# S32R372 register map
Vendor: Freescale Semiconductor, Inc.; Series: Qorivva; File version: 1.6
Registers are 32-bit, read-write, reset 0x0 unless marked. A register's access mark holds for its fields unless they carry their own. Offsets are from the block's base; [hi:lo] are bit positions; {n}, {i} and the like mark numbered series; 'fields as' and 'values as' point back to an identical list.

## MC_ME
Base 0xFFFB8000; register names take the prefix MC_ME_
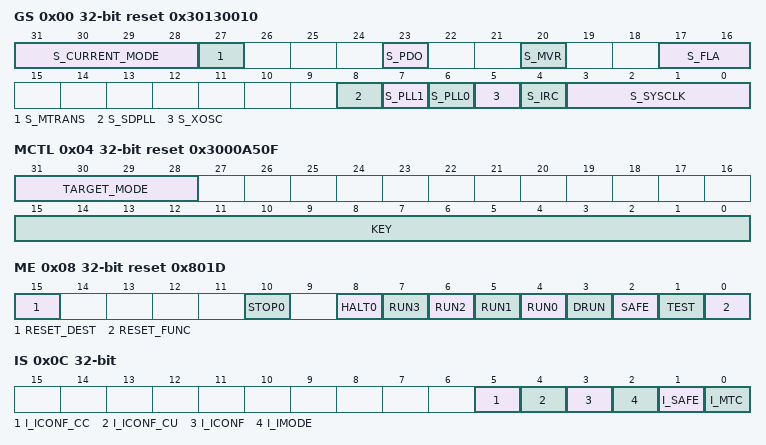
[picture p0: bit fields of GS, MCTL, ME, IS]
0x00 GS ro reset 0x30130010 — Global Status Register
  [31:28] S_CURRENT_MODE — Current chip mode status
    0=RESET; 1=TEST; 2=SAFE; 3=DRUN; {v}=RUN{v-4} (v=4..7); 8=HALT0; 10=STOP0
  [27] S_MTRANS — Mode transition status
    0=Mode transition process is not active; 1=Mode transition is ongoing
  [23] S_PDO — Output power-down status - This bit specifies output power-down status of I/Os
    0=No automatic safe gating of I/Os used and pads power sequence driver is enabled; 1=In SAFE/TEST modes, outputs of pads are forced to high impedance state and the pads power sequence driver is disabled. The inputs are level unchanged. In STOP0 mode, only the pad power sequence driver is disabled, but the state of the output remains functional.
  [20] S_MVR — Main voltage regulator status
    0=Main voltage regulator is not ready; 1=Main voltage regulator is ready for use
  [17:16] S_FLA — Flash availability status
    3=Flash is in normal mode and available for use
  [8] S_SDPLL — SDPLL status
    0=SDPLL is not stable; 1=SDPLL is providing a stable clock
  [7] S_PLL1 — PLL1 status
    0=PLL1 is not stable; 1=PLL1 is providing a stable clock
  [6] S_PLL0 — PLL0 status
    0=PLL0 is not stable; 1=PLL0 is providing a stable clock
  [5] S_XOSC — XOSC status S_XOSC alone should not be relied on
    0=XOSC is not stable; 1=XOSC is providing a stable clock
  [4] S_IRC — IRC status
    0=IRC is not stable; 1=IRC is providing a stable clock
  [3:0] S_SYSCLK — System clock switch status - These bits specify the system clock currently used by the system.
    0=IRC_CLK; 1=XOSC_CLK; 2=PLL0_PHI_CLK; 4=PLL1_PHI_CLK; 15=system clock is disabled
0x04 MCTL reset 0x3000A50F — Mode Control Register
  [31:28] TARGET_MODE — Target chip mode - These bits provide the target chip mode to be entered by software programming
    0=RESET (triggers a 'functional' reset event); 1=TEST; 2=SAFE; 3=DRUN; {v}=RUN{v-4} (v=4..7); 8=HALT0; 10=STOP0; 15=RESET (triggers a 'destructive' reset event)
  [15:0] KEY wo — Control key - These bits enable write access to this register
0x08 ME reset 0x801D — Mode Enable Register
  [15] RESET_DEST ro — 'destructive' RESET mode enable
    1='destructive' RESET mode is enabled
  [10] STOP0 — STOP0 mode enable
    0=STOP0 mode is disabled; 1=STOP0 mode is enabled
  [8] HALT0 — HALT0 mode enable
    0=HALT0 mode is disabled; 1=HALT0 mode is enabled
  [7] RUN3 — RUN3 mode enable
    0=RUN3 mode is disabled; 1=RUN3 mode is enabled
  [6] RUN2 — RUN2 mode enable
    0=RUN2 mode is disabled; 1=RUN2 mode is enabled
  [5] RUN1 — RUN1 mode enable
    0=RUN1 mode is disabled; 1=RUN1 mode is enabled
  [4] RUN0 ro — RUN0 mode enable
    1=RUN0 mode is enabled
  [3] DRUN ro — DRUN mode enable
    1=DRUN mode is enabled
  [2] SAFE ro — SAFE mode enable
    1=SAFE mode is enabled
  [1] TEST — TEST mode enable
    0=TEST mode is disabled; 1=TEST mode is enabled
  [0] RESET_FUNC ro — 'functional' RESET mode enable
    1='functional' RESET mode is enabled
0x0C IS — Interrupt Status Register
  [5] I_ICONF_CC — Invalid mode configuration interrupt (core configuration) - This bit is set if a write access to one of the ME_CADDRn registers is attempted while a mode transition is in progress
    0=No write to an ME_CADDRn register was attempted during an ongoing mode transition; 1=A write to an ME_CADDRn register was attempted during an ongoing mode transition
  [4] I_ICONF_CU — Invalid mode configuration interrupt (Clock Usage) - This bit is set during a mode transition if a clock which is required to be on by an enabled peripheral is configured to be turned off
    0=No invalid mode configuration (clock usage) interrupt occurred; 1=Invalid mode configuration (clock usage) interrupt is pending
  [3] I_ICONF — Invalid mode configuration interrupt - This bit is set whenever a write operation to ME_<mode>_MC registers with invalid mode configuration is attempted
    0=No invalid mode configuration interrupt occurred; 1=Invalid mode configuration interrupt is pending
  [2] I_IMODE — Invalid mode interrupt - This bit is set whenever an invalid mode transition is requested
    0=No invalid mode interrupt occurred; 1=Invalid mode interrupt is pending
  [1] I_SAFE — SAFE mode interrupt - This bit is set whenever the chip enters SAFE mode on hardware requests generated in the system
    0=No SAFE mode interrupt occurred; 1=SAFE mode interrupt is pending
  [0] I_MTC — Mode transition complete interrupt - This bit is set whenever the mode transition process completes (S_MTRANS transits from 1 to 0)
    0=No mode transition complete interrupt occurred; 1=Mode transition complete interrupt is pending
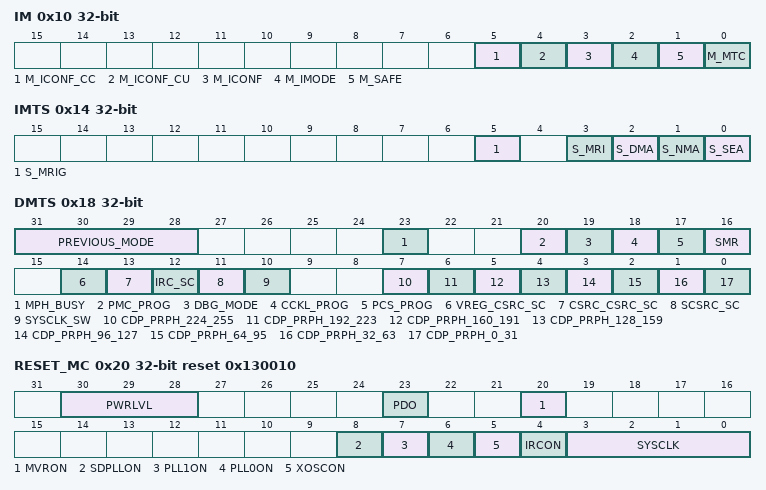
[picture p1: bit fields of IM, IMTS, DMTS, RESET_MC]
0x10 IM — Interrupt Mask Register
  [5] M_ICONF_CC — Invalid mode configuration (core configuration) interrupt mask
    0=Invalid mode interrupt is masked; 1=Invalid mode interrupt is enabled
  [4] M_ICONF_CU — Invalid mode configuration (clock usage) interrupt mask
    values as M_ICONF_CC
  [3] M_ICONF — Invalid mode configuration interrupt mask
    values as M_ICONF_CC
  [2] M_IMODE — Invalid mode interrupt mask
    values as M_ICONF_CC
  [1] M_SAFE — SAFE mode interrupt mask
    0=SAFE mode interrupt is masked; 1=SAFE mode interrupt is enabled
  [0] M_MTC — Mode transition complete interrupt mask
    0=Mode transition complete interrupt is masked; 1=Mode transition complete interrupt is enabled
0x14 IMTS — Invalid Mode Transition Status Register
  [5] S_MRIG — S_MRIG Mode Request Ignored status - This bit is set whenever a new mode is requested while a transition to the SAFE mode is in progress
  [3] S_MRI — Mode Request Illegal status - This bit is set whenever the target mode requested is not a valid mode with respect to current mode
    0=Target mode requested is not illegal with respect to current mode; 1=Target mode requested is illegal with respect to current mode
  [2] S_DMA — Disabled Mode Access status - This bit is set whenever the target mode requested is one of those disabled modes determined by ME_ME register
    0=Target mode requested is not a disabled mode; 1=Target mode requested is a disabled mode
  [1] S_NMA — Non-existing Mode Access status - This bit is set whenever the target mode requested is one of those non existing modes determined by ME_ME register
    0=Target mode requested is an existing mode; 1=Target mode requested is a non-existing mode
  [0] S_SEA — SAFE Event Active status - This bit is set whenever the chip is in SAFE mode, SAFE event bit is pending and a new mode requested other than RESET/SAFE modes
    0=No new mode requested other than RESET/SAFE while SAFE event is pending; 1=New mode requested other than RESET/SAFE while SAFE event is pending
0x18 DMTS ro — Debug Mode Transition Status Register
  [31:28] PREVIOUS_MODE — Previous chip mode - These bits show the mode in which the chip was prior to the latest change to the current mode
    values as GS.S_CURRENT_MODE
  [23] MPH_BUSY — MC_ME/MC_PCU Handshake Busy indicator - This bit is set if the MC_ME has requested a mode change from the MC_PCU and the MC_PCU has not yet completed its handshake
    0=Handshake is not busy; 1=Handshake is busy
  [20] PMC_PROG — MC_PCU Mode Change in Progress indicator - This bit is set if the MC_PCU is in the process of powering up or down power domains
    0=Power-up/down transition is not in progress; 1=Power-up/down transition is in progress
  [19] DBG_MODE — Debug mode indicator - This bit is set while the chip is in debug mode.
    0=The chip is not in debug mode; 1=The chip is in debug mode
  [18] CCKL_PROG — Core Clock Enable/Disable in Progress - This bit is set while any core's clock is in the process of being enabled or disabled
    0=No core clock is being enabled or disabled; 1=A core clock is being enabled or disabled
  [17] PCS_PROG — Progressive System Clock Switching in Progress - This bit is set while the progressive system clock switching process is in progress
    0=PCS is not in progress; 1=PCS is in progress
  [16] SMR — SAFE mode request from MC_RGM is active indicator - This bit is set if a hardware SAFE mode request has been triggered
    0=A SAFE mode request is not active; 1=A SAFE mode request is active
  [14] VREG_CSRC_SC — Main VREG dependent Clock Source State Change during mode transition indicator - This bit is set when a clock source which depends on the main voltage regulator to be powered-up is requested to change its power up/down state
    0=No state change is taking place; 1=A state change is taking place
  [13] CSRC_CSRC_SC — (Other) Clock Source dependent Clock Source State Change during mode transition indicator - This bit is set when a clock source which depends on another clock source to be powered-up is requested to change its power up/down state
    values as VREG_CSRC_SC
  [12] IRC_SC — IRC State Change during mode transition indicator - This bit is set when the IRC is requested to change its power up/down state
    values as VREG_CSRC_SC
  [11] SCSRC_SC — Secondary Clock Sources State Change during mode transition indicator - This bit is set when a secondary clock source is requested to change its power up/down state
    values as VREG_CSRC_SC
  [10] SYSCLK_SW — System Clock Switching pending status -
    0=No system clock source switching is pending; 1=A system clock source switching is pending
  [7] CDP_PRPH_224_255 — Clock Disable Process Pending status for Peripherals 224
    0=No peripheral clock disabling is pending; 1=Clock disabling is pending for at least one peripheral
  [6] CDP_PRPH_192_223 — Clock Disable Process Pending status for Peripherals 192
    values as CDP_PRPH_224_255
  [5] CDP_PRPH_160_191 — Clock Disable Process Pending status for Peripherals 160
    values as CDP_PRPH_224_255
  [4] CDP_PRPH_128_159 — Clock Disable Process Pending status for Peripherals 128
    values as CDP_PRPH_224_255
  [3] CDP_PRPH_96_127 — Clock Disable Process Pending status for Peripherals 96
    values as CDP_PRPH_224_255
  [2] CDP_PRPH_64_95 — Clock Disable Process Pending status for Peripherals 64
    values as CDP_PRPH_224_255
  [1] CDP_PRPH_32_63 — Clock Disable Process Pending status for Peripherals 32
    values as CDP_PRPH_224_255
  [0] CDP_PRPH_0_31 — Clock Disable Process Pending status for Peripherals 0
    values as CDP_PRPH_224_255
0x20 RESET_MC ro reset 0x130010 — RESET Mode Configuration Register
  [30:28] PWRLVL — Power level - These bits indicate the relative power consumption level of this mode with respect to that of other modes
  [23] PDO — I/O output power-down control-This bit controls the output power-down of I/Os.
    0=No automatic safe gating of I/Os used and pads power sequence driver is enabled
  [20] MVRON — Main voltage regulator control - This bit specifies whether main voltage regulator is switched off or not while entering this mode
    1=Main voltage regulator is switched on
  [8] SDPLLON — SDPLL control
    0=SDPLL is switched off
  [7] PLL1ON — PLL1 control
    0=PLL1 is switched off
  [6] PLL0ON — PLL0 control
    0=PLL0 is switched off
  [5] XOSCON — XOSC control
    0=XOSC is switched off
  [4] IRCON — IRC control
    1=IRC is switched on
  [3:0] SYSCLK — System clock switch control - These bits specify the system clock to be used by the system.
    0=IRC_CLK; 15=system clock is disabled in TEST mode, reserved in all other modes
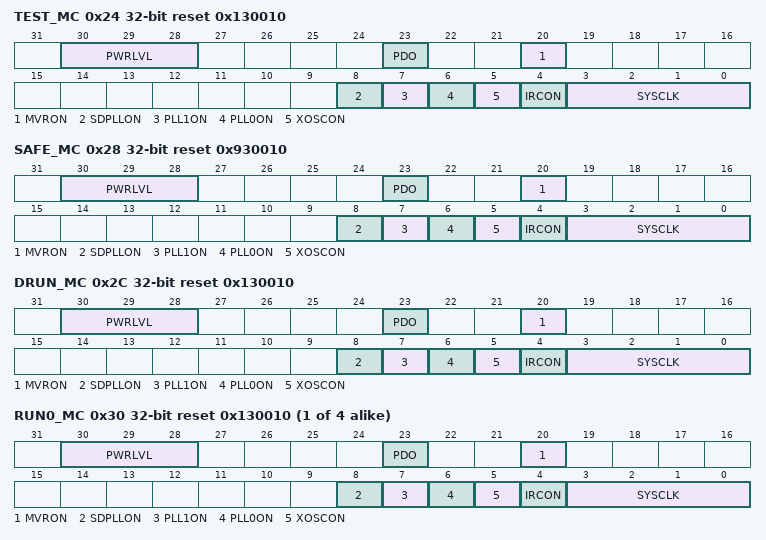
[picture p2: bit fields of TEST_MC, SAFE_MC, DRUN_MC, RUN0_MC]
0x24 TEST_MC reset 0x130010 — TEST Mode Configuration Register
  [30:28] PWRLVL — Power level - These bits indicate the relative power consumption level of this mode with respect to that of other modes
  [23] PDO — I/O output power-down control - This bit controls the output power-down of I/Os.
    0=No automatic safe gating of I/Os used and pads power sequence driver is enabled; 1=In SAFE/TEST modes, outputs of pads are forced to high impedance state and pads power sequence driver is disabled. The inputs are level unchanged. In STOP0 mode, only the pad power sequence driver is disabled, but the state of the output remains functional.
  [20] MVRON ro — Main voltage regulator control - This bit specifies whether main voltage regulator is switched off or not while entering this mode
    1=Main voltage regulator is switched on
  [8] SDPLLON — SDPLL control
    0=SDPLL is switched off; 1=SDPLL is switched on
  [7] PLL1ON — PLL1 control
    0=PLL1 is switched off; 1=PLL1is switched on
  [6] PLL0ON — PLL0 control
    0=PLL0 is switched off; 1=PLL0 is switched on
  [5] XOSCON — XOSC control
    0=XOSC is switched off; 1=XOSC is switched on
  [4] IRCON — IRC control
    0=IRC is switched off; 1=IRC is switched on
  [3:0] SYSCLK — System clock switch control - These bits specify the system clock to be used by the system.
    0=IRC_CLK; 1=XOSC_CLK; 2=PLL0_PHI_CLK; 4=PLL1_PHI_CLK; 15=system clock is disabled in TEST mode, reserved in all other modes
0x28 SAFE_MC reset 0x930010 — SAFE Mode Configuration Register
  [30:28] PWRLVL — Power level - These bits indicate the relative power consumption level of this mode with respect to that of other modes
  [23] PDO — I/O output power-down control - This bit controls the output power-down of I/Os.
    values as TEST_MC.PDO
  [20] MVRON ro — Main voltage regulator control - This bit specifies whether main voltage regulator is switched off or not while entering this mode
    1=Main voltage regulator is switched on
  [8] SDPLLON ro — SDPLL control
    0=SDPLL is switched off
  [7] PLL1ON ro — PLL1 control
    0=PLL1 is switched off
  [6] PLL0ON ro — PLL0 control
    0=PLL0 is switched off
  [5] XOSCON ro — XOSC control
    0=XOSC is switched off
  [4] IRCON ro — IRC control
    1=IRC is switched on
  [3:0] SYSCLK ro — System clock switch control - These bits specify the system clock to be used by the system.
    values as RESET_MC.SYSCLK
0x2C DRUN_MC reset 0x130010 — DRUN Mode Configuration Register
  [30:28] PWRLVL — Power level - These bits indicate the relative power consumption level of this mode with respect to that of other modes
  [23] PDO ro — I/O output power-down control - This bit controls the output power-down of I/Os.
    values as TEST_MC.PDO
  [20] MVRON ro — Main voltage regulator control - This bit specifies whether main voltage regulator is switched off or not while entering this mode
    1=Main voltage regulator is switched on
  [8] SDPLLON — SDPLL control
    0=SDPLL is switched off; 1=SDPLL is switched on
  [7] PLL1ON — PLL1 control
    0=PLL1 is switched off; 1=PLL1 is switched on
  [6] PLL0ON — PLL0 control
    0=PLL0 is switched off; 1=PLL0 is switched on
  [5] XOSCON — XOSC control
    0=XOSC is switched off; 1=XOSC is switched on
  [4] IRCON ro — IRC control
    0=IRC is switched off; 1=IRC is switched on
  [3:0] SYSCLK — System clock switch control - These bits specify the system clock to be used by the system.
    values as TEST_MC.SYSCLK
{0x30+4i} RUN{i}_MC (i=0..3) reset 0x130010 — RUN0 3 Mode Configuration Register
  fields as DRUN_MC
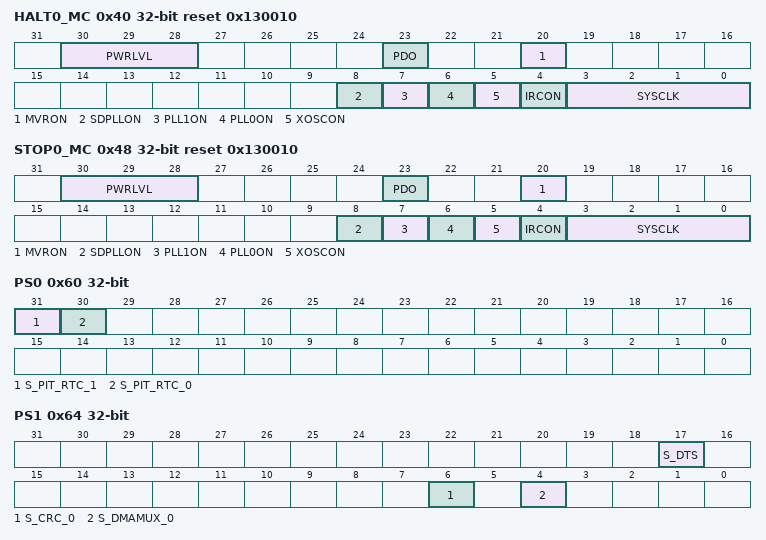
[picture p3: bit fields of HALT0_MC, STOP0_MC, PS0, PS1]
0x40 HALT0_MC reset 0x130010 — HALT0 Mode Configuration Register
  [30:28] PWRLVL ro — Power level - These bits indicate the relative power consumption level of this mode with respect to that of other modes
  [23] PDO ro — I/O output power-down control - This bit controls the output power-down of I/Os.
    values as TEST_MC.PDO
  [20] MVRON ro — Main voltage regulator control - This bit specifies whether main voltage regulator is switched off or not while entering this mode
    1=Main voltage regulator is switched on
  [8] SDPLLON — SDPLL control
    0=SDPLL is switched off; 1=SDPLL is switched on
  [7] PLL1ON — PLL1 control
    0=PLL1 is switched off; 1=PLL1 is switched on
  [6] PLL0ON — PLL0 control
    0=PLL0 is switched off; 1=PLL0 is switched on
  [5] XOSCON — XOSC control
    0=XOSC is switched off; 1=XOSC is switched on
  [4] IRCON ro — IRC control
    0=IRC is switched off; 1=IRC is switched on
  [3:0] SYSCLK — System clock switch control - These bits specify the system clock to be used by the system.
    values as TEST_MC.SYSCLK
0x48 STOP0_MC reset 0x130010 — STOP0 Mode Configuration Register
  [30:28] PWRLVL ro — Power level - These bits indicate the relative power consumption level of this mode with respect to that of other modes
  [23] PDO — I/O output power-down control - This bit controls the output power-down of I/Os.
    values as TEST_MC.PDO
  [20] MVRON ro — Main voltage regulator control - This bit specifies whether main voltage regulator is switched off or not while entering this mode
    1=Main voltage regulator is switched on
  [8] SDPLLON ro — SDPLL control
    0=SDPLL is switched off; 1=SDPLL is switched on
  [7] PLL1ON ro — PLL1 control
    0=PLL1 is switched off; 1=PLL1 is switched on
  [6] PLL0ON ro — PLL0 control
    0=PLL0 is switched off; 1=PLL0 is switched on
  [5] XOSCON — XOSC control
    0=XOSC is switched off; 1=XOSC is switched on
  [4] IRCON ro — IRC control
    0=IRC is switched off; 1=IRC is switched on
  [3:0] SYSCLK ro — System clock switch control - These bits specify the system clock to be used by the system.
    values as TEST_MC.SYSCLK
0x60 PS0 ro — Peripheral Status Register 0
  [31] S_PIT_RTC_1 — Peripheral status - These bits specify the current status of each peripheral which is controlled by the MC_ME
    0=Peripheral is frozen; 1=Peripheral is active
  [30] S_PIT_RTC_0 — Peripheral status - These bits specify the current status of each peripheral which is controlled by the MC_ME
    0=Peripheral is frozen; 1=Peripheral is active
0x64 PS1 ro — Peripheral Status Register 1
  [all] fields
    0=Peripheral is frozen; 1=Peripheral is active
  [17] S_DTS — Peripheral status - These bits specify the current status of each peripheral which is controlled by the MC_ME
  [6] S_CRC_0 — Peripheral status - These bits specify the current status of each peripheral which is controlled by the MC_ME
  [4] S_DMAMUX_0 — Peripheral status - These bits specify the current status of each peripheral which is controlled by the MC_ME
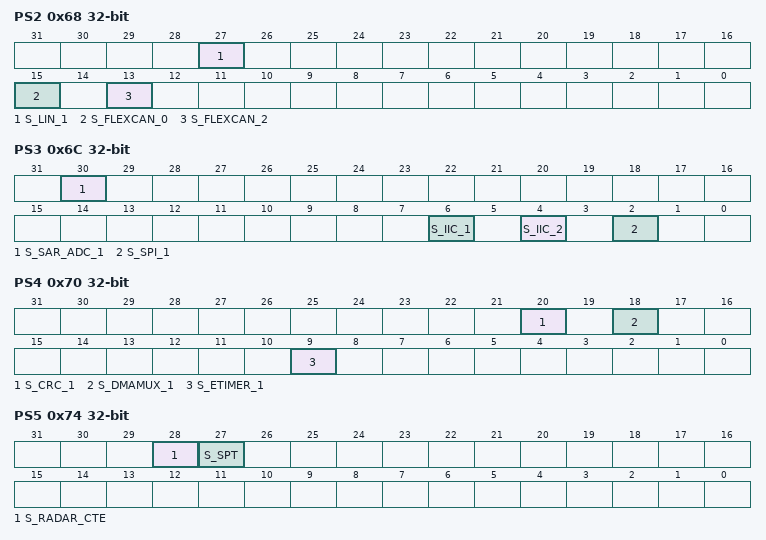
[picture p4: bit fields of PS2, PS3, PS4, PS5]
0x68 PS2 ro — Peripheral Status Register 2
  [all] fields
    0=Peripheral is frozen; 1=Peripheral is active
  [27] S_LIN_1 — Peripheral status - These bits specify the current status of each peripheral which is controlled by the MC_ME
  [15] S_FLEXCAN_0 — Peripheral status - These bits specify the current status of each peripheral which is controlled by the MC_ME
  [13] S_FLEXCAN_2 — Peripheral status - These bits specify the current status of each peripheral which is controlled by the MC_ME
0x6C PS3 ro — Peripheral Status Register 3
  [all] fields
    0=Peripheral is frozen; 1=Peripheral is active
  [30] S_SAR_ADC_1 — Peripheral status - These bits specify the current status of each peripheral which is controlled by the MC_ME
  [6] S_IIC_1 — Peripheral status - These bits specify the current status of each peripheral which is controlled by the MC_ME
  [4] S_IIC_2 — Peripheral status - These bits specify the current status of each peripheral which is controlled by the MC_ME
  [2] S_SPI_1 — Peripheral status - These bits specify the current status of each peripheral which is controlled by the MC_ME
0x70 PS4 ro — Peripheral Status Register 4
  [all] fields
    0=Peripheral is frozen; 1=Peripheral is active
  [20] S_CRC_1 — Peripheral status - These bits specify the current status of each peripheral which is controlled by the MC_ME
  [18] S_DMAMUX_1 — Peripheral status - These bits specify the current status of each peripheral which is controlled by the MC_ME
  [9] S_ETIMER_1 — Peripheral status - These bits specify the current status of each peripheral which is controlled by the MC_ME
0x74 PS5 ro — Peripheral Status Register 5
  [28] S_RADAR_CTE — Peripheral status - These bits specify the current status of each peripheral which is controlled by the MC_ME
    0=Peripheral is frozen; 1=Peripheral is active
  [27] S_SPT — Peripheral status - These bits specify the current status of each peripheral which is controlled by the MC_ME
    0=Peripheral is frozen; 1=Peripheral is active
0x78 PS6 ro — Peripheral Status Register 6
  [17] S_DSPI_2 — Peripheral status - These bits specify the current status of each peripheral which is controlled by the MC_ME
    0=Peripheral is frozen; 1=Peripheral is active
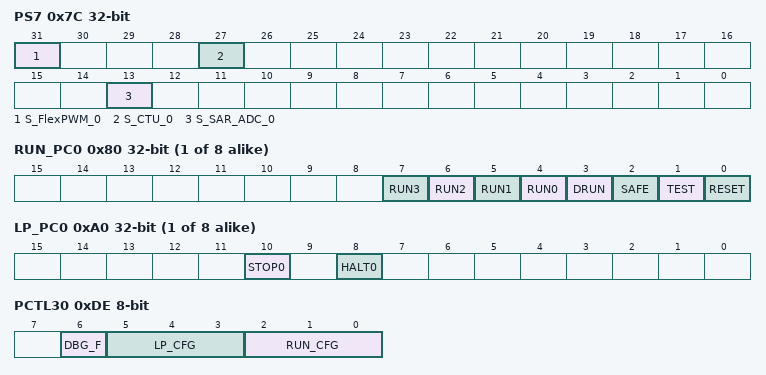
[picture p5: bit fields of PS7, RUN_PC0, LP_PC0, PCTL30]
0x7C PS7 ro — Peripheral Status Register 7
  [all] fields
    0=Peripheral is frozen; 1=Peripheral is active
  [31] S_FlexPWM_0 — Peripheral status - These bits specify the current status of each peripheral which is controlled by the MC_ME
  [27] S_CTU_0 — Peripheral status - These bits specify the current status of each peripheral which is controlled by the MC_ME
  [13] S_SAR_ADC_0 — Peripheral status - These bits specify the current status of each peripheral which is controlled by the MC_ME
{0x80+4i} RUN_PC{i} (i=0..7) — Run Peripheral Configuration Register
  [all] fields
    0=Peripheral is frozen with clock gated; 1=Peripheral is active
  [n+4] RUN{n} (n=0..3) — Peripheral control during RUN{n}
  [3] DRUN — Peripheral control during DRUN
  [2] SAFE — Peripheral control during SAFE
  [1] TEST — Peripheral control during TEST
  [0] RESET ro — Peripheral control during RESET
{0xA0+4i} LP_PC{i} (i=0..7) — Low-Power Peripheral Configuration Register
  [10] STOP0 — Peripheral control during STOP0
    values as the fields of RUN_PC0
  [8] HALT0 — Peripheral control during HALT0
    values as the fields of RUN_PC0
0xDE PCTL30 8-bit — PIT_RTC_0 Peripheral Control Register
  [6] DBG_F — Peripheral control in debug mode - This bit controls the state of the peripheral in debug mode This feature is useful to freeze the peripheral state while entering debug
    0=Peripheral state depends on RUN_CFG/LP_CFG bits and the chip mode; 1=Peripheral is frozen if not already frozen in chip modes
  [5:3] LP_CFG — Peripheral configuration select for non-run modes - These bits associate a configuration as defined in the ME_LP_PC0
    {v}=Selects ME_LP_PC{v} configuration (v=0..7)
  [2:0] RUN_CFG — Peripheral configuration select for run modes - These bits associate a configuration as defined in the ME_RUN_PC0
    {v}=Selects ME_RUN_PC{v} configuration (v=0..7)
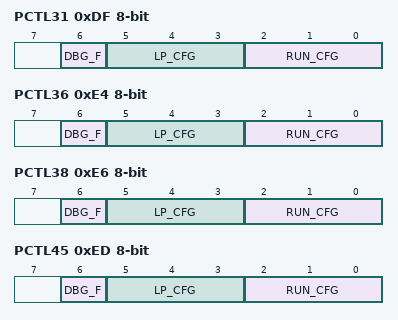
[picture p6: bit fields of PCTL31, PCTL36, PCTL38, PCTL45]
0xDF PCTL31 8-bit — PIT_RTC_1 Peripheral Control Register
  fields as PCTL30
0xE4 PCTL36 8-bit — DMAMUX_0 Peripheral Control Register
  fields as PCTL30
0xE6 PCTL38 8-bit — CRC_0 Peripheral Control Register
  fields as PCTL30
0xED PCTL45 8-bit — JTAGM Peripheral Control Register
  fields as PCTL30
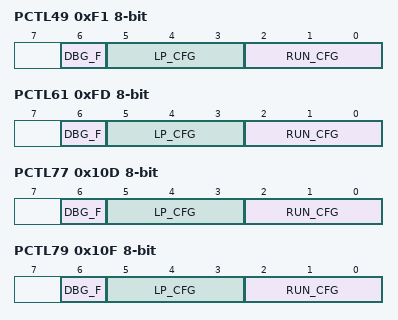
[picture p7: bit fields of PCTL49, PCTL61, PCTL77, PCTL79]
0xF1 PCTL49 8-bit — DTS Peripheral Control Register
  fields as PCTL30
0xFD PCTL61 8-bit — MIPI Peripheral Control Register
  fields as PCTL30
0x10D PCTL77 8-bit — FLEXCAN_2 Peripheral Control Register
  fields as PCTL30
0x10F PCTL79 8-bit — FLEXCAN_0 Peripheral Control Register
  fields as PCTL30
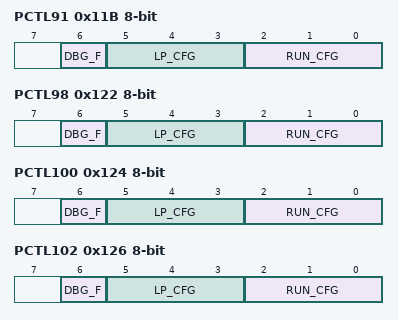
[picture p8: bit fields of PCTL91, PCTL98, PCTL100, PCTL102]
0x11B PCTL91 8-bit — LINFlex_1 Peripheral Control Register
  fields as PCTL30
0x122 PCTL98 8-bit — SPI_1 Peripheral Control Register
  fields as PCTL30
0x124 PCTL100 8-bit — IIC_2 Peripheral Control Register
  fields as PCTL30
0x126 PCTL102 8-bit — IIC_1 Peripheral Control Register
  fields as PCTL30
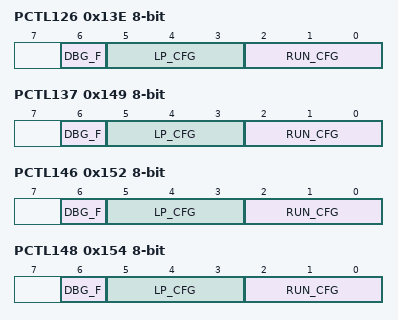
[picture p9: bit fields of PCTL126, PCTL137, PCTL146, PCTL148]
0x13E PCTL126 8-bit — SAR_ADC_1 Peripheral Control Register
  fields as PCTL30
0x149 PCTL137 8-bit — ETIMER_1 Peripheral Control Register
  fields as PCTL30
0x152 PCTL146 8-bit — DMAMUX_1 Peripheral Control Register
  fields as PCTL30
0x154 PCTL148 8-bit — CRC_1 Peripheral Control Register
  fields as PCTL30
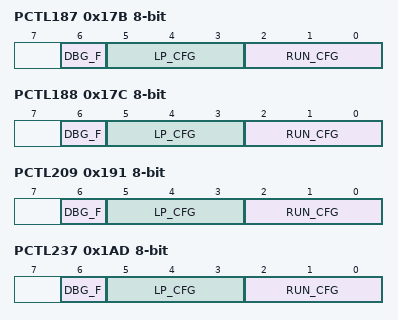
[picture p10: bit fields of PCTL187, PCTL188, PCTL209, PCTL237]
0x17B PCTL187 8-bit — SPT Peripheral Control Register
  fields as PCTL30
0x17C PCTL188 8-bit — RADAR_CTE Peripheral Control Register
  fields as PCTL30
0x191 PCTL209 8-bit — SPI_2 Peripheral Control Register
  fields as PCTL30
0x1AD PCTL237 8-bit — SAR_ADC_0 Peripheral Control Register
  fields as PCTL30
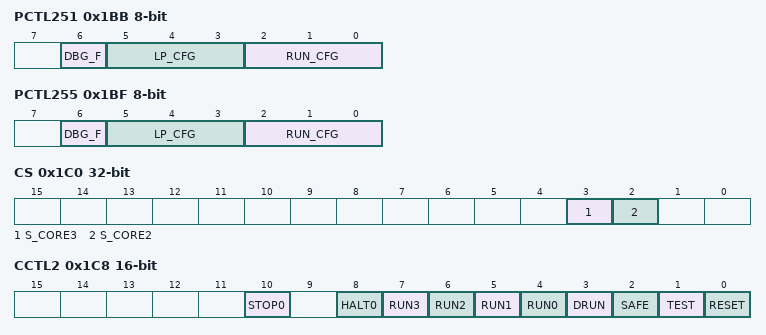
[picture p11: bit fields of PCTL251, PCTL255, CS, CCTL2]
0x1BB PCTL251 8-bit — CTU_0 Peripheral Control Register
  fields as PCTL30
0x1BF PCTL255 8-bit — FlexPWM_0 Peripheral Control Register
  fields as PCTL30
0x1C0 CS ro reset not defined — Core Status Register
  [3] S_CORE3 — Core 3 status - This bits specifies the current status of z7b which is controlled by the ME_CCTL3 register
    0=z7b is disabled; 1=z7b is running
  [2] S_CORE2 — Core 2 status - This bits specifies the current status of z7a which is controlled by the ME_CCTL2 register
    0=z7a is disabled; 1=z7a is running
0x1C8 CCTL2 16-bit — Core Control Register
  [10] STOP0 ro — Core control during STOP0 - z7a is always disabled during STOP0
  [8] HALT0 ro — Core control during HALT0 - z7a is always disabled during HALT0
  [7] RUN3 — Core control during RUN3
    0=z7a is disabled with clock gated; 1=z7a is running
  [6] RUN2 — Core control during RUN2
    0=z7a is disabled with clock gated; 1=z7a is running
  [5] RUN1 — Core control during RUN1
    0=z7a is disabled with clock gated; 1=z7a is running
  [4] RUN0 — Core control during RUN0
    0=z7a is frozen with clock gated; 1=z7a is running
  [3] DRUN — Core control during DRUN
    0=z7a is frozen with clock gated; 1=z7a is running
  [2] SAFE — Core control during SAFE
    0=z7a is frozen with clock gated; 1=z7a is running
  [1] TEST — Core control during TEST
    0=z7a is frozen with clock gated; 1=z7a is running
  [0] RESET ro — Core control during RESET - z7a is always disabled during RESET
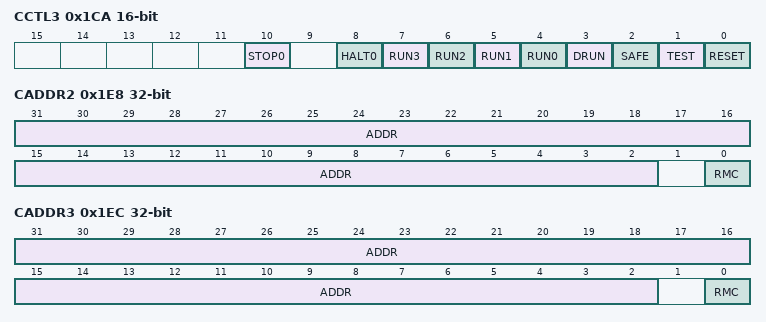
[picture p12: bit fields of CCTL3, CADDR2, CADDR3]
0x1CA CCTL3 16-bit — Core Control Register
  [10] STOP0 ro — Core control during STOP0 - z7b is always disabled during STOP0
  [8] HALT0 ro — Core control during HALT0 - z7b is always disabled during HALT0
  [7] RUN3 — Core control during RUN3
    0=z7b is disabled with clock gated; 1=z7b is running
  [6] RUN2 — Core control during RUN2
    0=z7b is disabled with clock gated; 1=z7b is running
  [5] RUN1 — Core control during RUN1
    0=z7b is disabled with clock gated; 1=z7b is running
  [4] RUN0 — Core control during RUN0
    0=z7b is frozen with clock gated; 1=z7b is running
  [3] DRUN — Core control during DRUN
    0=z7b is frozen with clock gated; 1=z7b is running
  [2] SAFE — Core control during SAFE
    0=z7b is frozen with clock gated; 1=z7b is running
  [1] TEST — Core control during TEST
    0=z7b is frozen with clock gated1 z7b is running
  [0] RESET ro — Core control during RESET - z7b is always disabled during RESET
0x1E8 CADDR2 — Core Control Registers
  [31:2] ADDR — Core Address - This field is used by z7a as the boot address (32-bit word aligned) when z7a next exits reset
  [0] RMC — Reset on Mode Change - z7a will be reset on the next mode change that has z7a configured to be running in the target mode
    0=z7a will not be reset on the next mode change; 1=z7a will be reset on the next mode change that has z7a configured to be running in the target mode
0x1EC CADDR3 — Core Control Registers
  [31:2] ADDR — Core Address - This field is used by z7b as the boot address (32-bit word aligned) when z7b next exits reset
  [0] RMC — Reset on Mode Change - z7b will be reset on the next mode change that has z7b configured to be running in the target mode
    0=z7b will not be reset on the next mode change; 1=z7b will be reset on the next mode change that has z7b configured to be running in the target mode
